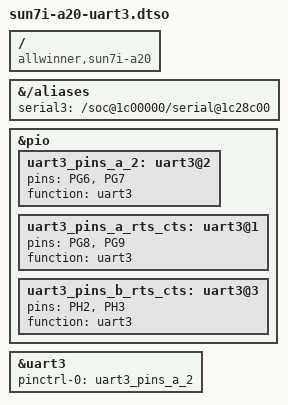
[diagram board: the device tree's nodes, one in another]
/dts-v1/;
/plugin/;

/ {
	compatible = "allwinner,sun7i-a20";

	fragment@0 {
		target-path = "/aliases";
		__overlay__ {
			serial3 = "/soc@1c00000/serial@1c28c00";
		};
	};

	fragment@1 {
		target = <&pio>;
		__overlay__ {
			uart3_pins_a_2: uart3@2 {
				pins = "PG6", "PG7";
				function = "uart3";
			};

			uart3_pins_a_rts_cts: uart3@1 {
				pins = "PG8", "PG9";
				function = "uart3";
			};

			uart3_pins_b_rts_cts: uart3@3 {
				pins = "PH2", "PH3";
				function = "uart3";
			};
		};
	};

	fragment@2 {
		target = <&uart3>;
		 __overlay__ {
			pinctrl-names = "default";
			pinctrl-0 = <&uart3_pins_a_2>;
			status = "okay";
		};
	};
};
